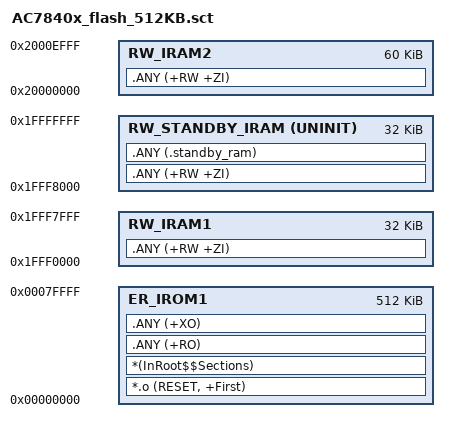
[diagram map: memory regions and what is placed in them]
; *************************************************************
; *** Scatter-Loading Description File generated by uVision ***
; *************************************************************

LR_IROM1 0x00000000 0x0080000  {    ; load region size_region
  ER_IROM1 0x00000000 0x0080000  {  ; load address = execution address
   *.o (RESET, +First)
   *(InRoot$$Sections)
   .ANY (+RO)
   .ANY (+XO)
  }

  RW_IRAM1 0x1FFF0000 0x00010000-0x8000  {  ; SRAM_L
   .ANY (+RW +ZI)
  }

  RW_STANDBY_IRAM 0x1FFF8000 UNINIT 0x8000  {  ; standby power mode retention RAM
   .ANY (+RW +ZI)
   .ANY (.standby_ram)
  }

  RW_IRAM2 0x20000000 0x0000F000  {  ; SRAM_U
   .ANY (+RW +ZI)
  }
}

